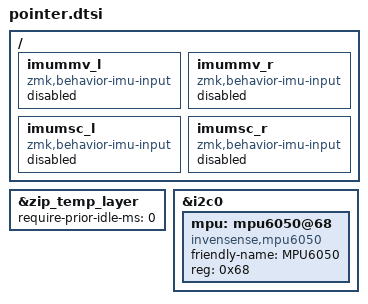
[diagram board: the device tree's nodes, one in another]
#include <input/processors.dtsi>
#include <dt-bindings/zmk/input_transform.h>
#include <zmk-imu-input.h>

/ {
  // Mouse Movement
  imummv_l: imummv_l {
    compatible = "zmk,behavior-imu-input";
    status = "disabled";
    #binding-cells = <0>;
  };

  imummv_r: imummv_r {
    compatible = "zmk,behavior-imu-input";
    status = "disabled";
    #binding-cells = <0>;
  };

  // Mouse Scrollling
  imumsc_l: imumsc_l {
    compatible = "zmk,behavior-imu-input";
    status = "disabled";
    #binding-cells = <0>;
  };

  // Mouse Scrollling
  imumsc_r: imumsc_r {
    compatible = "zmk,behavior-imu-input";
    status = "disabled";
    #binding-cells = <0>;
  };
};

&zip_temp_layer {
  status = "okay";
  require-prior-idle-ms = <0>;
};

&i2c0 {
  mpu: mpu6050@68 {
    compatible = "invensense,mpu6050";
    status = "okay";
    friendly-name = "MPU6050";
    reg = <0x68>;
  };
};


